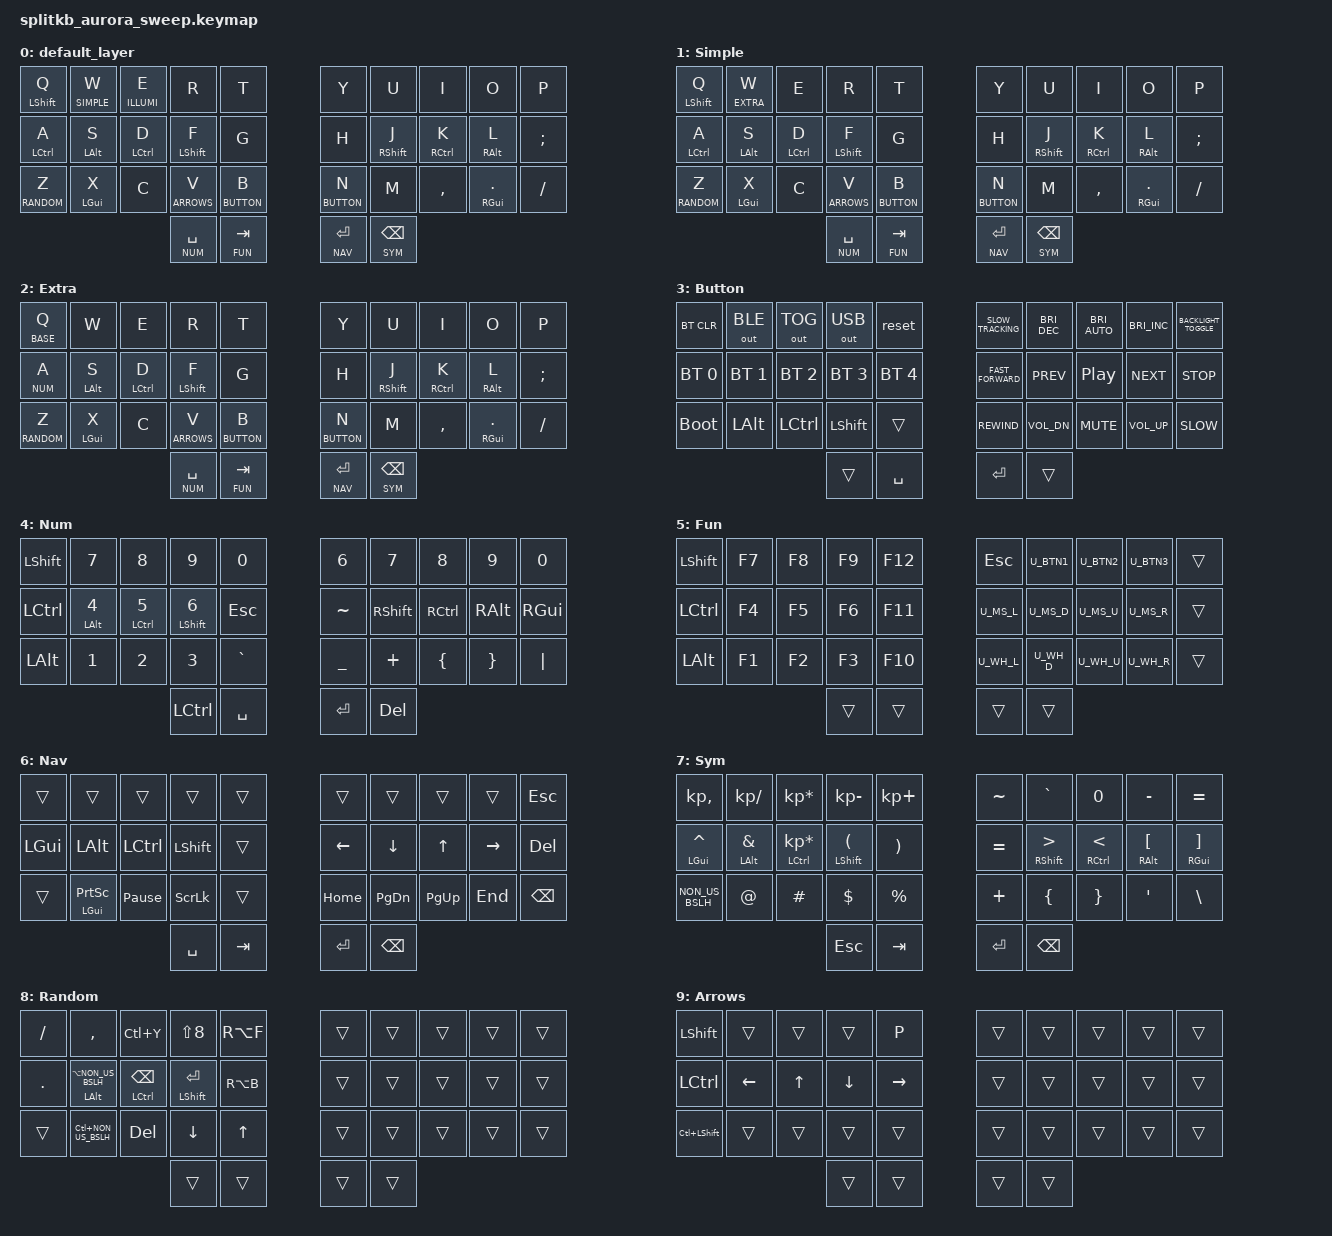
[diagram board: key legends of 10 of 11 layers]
/*
 * Copyright (c) 2020 The ZMK Contributors
 *
 * SPDX-License-Identifier: MIT
 */

#include <behaviors.dtsi>
#include <dt-bindings/zmk/keys.h>
#include <dt-bindings/zmk/bt.h>
#include <dt-bindings/zmk/outputs.h>
#include <dt-bindings/zmk/mouse.h>
#include <dt-bindings/zmk/rgb.h>



#include "mousedefs.h"
// #include <dt-bindings/zmk/backlight.h>

#define BASE   0
#define SIMPLE 1
#define EXTRA  2
#define BUTTON 3
#define NUM    4
#define FUN    5
#define NAV    6
#define SYM    7
#define RANDOM 8
#define ARROWS 9
#define ILLUMI 10

&led_strip {
    chain-length = <23>;
};

/ {
    behaviors {
        hm: homerow_mods {
            compatible = "zmk,behavior-hold-tap";
            label = "homerow mods";
            #binding-cells = <2>;
            tapping_term_ms = <200>;
            flavor = "balanced";
            quick-tap-ms = <0>;
            bindings = <&kp>, <&kp>;
        };
        him: homerow_insta_mods {
            compatible = "zmk,behavior-hold-tap";
            label = "hm_insta_mods";
            #binding-cells = <2>;
			tapping-term-ms = <200>;
            flavor = "balanced";
            bindings = <&kp>, <&kp>;
            // hold-while-undecided;
        };
        hfm: homerow_fastmode {
            compatible = "zmk,behavior-hold-tap";
            label = "HOMEROW_FAST";
            #binding-cells = <2>;
            tapping_term_ms = <300>;
            flavor = "tap-preferred";
            bindings = <&kp>, <&kp>;
            // hold-while-undecided;
        };
        hcm: homerow_crazymode {
            compatible = "zmk,behavior-hold-tap";
            label = "HOMEROW_CRAZY";
            #binding-cells = <2>;
            tapping_term_ms = <0>;
            flavor = "balanced";
            bindings = <&kp>, <&kp>;
            retro-tap;
        };
        ltg: layer_toggler {
            compatible = "zmk,behavior-hold-tap";
            label = "LAYER_TOGGLER";
            #binding-cells = <2>;
            tapping_term_ms = <1200>;
            flavor = "tap-preferred";
            bindings = <&to>, <&kp>;
        };
        ltp: layer_tapper {
            compatible = "zmk,behavior-hold-tap";
            label = "LAYER_TAPPER";
            #binding-cells = <2>;
            tapping_term_ms = <200>;
            flavor = "balanced";
            bindings = <&mo>, <&kp>;
        };
    };
    
    keymap {
        compatible = "zmk,keymap";
        default_layer {
            bindings = <
   &him LSHFT Q    &ltg SIMPLE W  &ltp ILLUMI E  &kp R            &kp T           &kp Y            &kp U          &kp I        &kp O         &kp P
   &hm LCTRL A     &hm LALT S     &hm LCTRL D    &him LSHFT F     &kp G           &kp H            &hm RSHFT J    &hm RCTRL K  &hm RALT L    &kp SEMI
   &ltp RANDOM Z   &hm LGUI X     &kp C          &ltp ARROWS V    &ltp BUTTON B   &ltp BUTTON N    &kp M          &kp COMMA    &hm RGUI DOT  &kp FSLH
                                                 &ltp NUM SPACE   &ltp FUN TAB    &ltp NAV ENTER   &ltp SYM BSPC
            >;
        };
        simple_layer {
            label = "Simple";
// -----------------------------------------------------------------------------------------
// same as base, but smaller times
            bindings = <
   &him LSHFT Q    &ltg EXTRA W    &kp E         &kp R           &kp T           &kp Y           &kp U          &kp I         &kp O          &kp P
   &hm LCTRL A    &hm LALT S      &him LCTRL D   &him LSHFT F    &kp G           &kp H           &hfm RSHFT J   &hfm RCTRL K  &hfm RALT L    &kp SEMI
   &ltp RANDOM Z  &hfm LGUI X     &kp C         &ltp ARROWS V   &ltp BUTTON B   &ltp BUTTON N   &kp M          &kp COMMA     &hfm RGUI DOT  &kp FSLH
                                                &ltp NUM SPACE  &ltp FUN TAB    &ltp NAV ENTER  &ltp SYM BSPC
            >;
        };
        extra_layer {
            label = "Extra";
// -----------------------------------------------------------------------------------------
// Interrup activated modkeys
            bindings = <
   &ltg BASE Q    &kp W        &kp E         &kp R          &kp T           &kp Y          &kp U          &kp I         &kp O          &kp P 
   &ltp NUM A     &hcm LALT S  &hcm LCTRL D  &hfm LSHFT F   &kp G           &kp H          &hcm RSHIFT J  &hcm RCTRL K  &hcm RALT L    &kp SEMI 
   &ltp RANDOM Z  &hcm LGUI X  &kp C         &ltp ARROWS V  &ltp BUTTON B   &ltp BUTTON N  &kp M          &kp COMMA     &hcm RGUI DOT  &kp FSLH
                                             &ltp NUM SPC   &ltp FUN TAB    &ltp NAV RET   &ltp SYM BSPC
            >;
        };
        button_layer {
            label = "Button";
// -----------------------------------------------------------------------------------------
// |       | OBT | OTOG | OUSB | BOOT |   |     |      |       |      |     |
// |  BT1  | BT2 | BT3  | BT4  | BT5  |   |     | PREV | PLAYP | NEXT | STP |
// | BTCLR | BLE | UBT  |      | RST  |   |     | VDN  | MUTE  | VUP  |     |
//                      |      | SPC  |   | ENT | ALT  |
            bindings = <
   &bt BT_CLR    &out OUT_BLE  &out OUT_TOG  &out OUT_USB  &reset         &kp C_SLOW_TRACKING  &kp C_BRI_DEC  &kp C_BRI_AUTO  &kp C_BRI_INC  &kp C_BACKLIGHT_TOGGLE     
   &bt BT_SEL 0  &bt BT_SEL 1  &bt BT_SEL 2  &bt BT_SEL 3  &bt BT_SEL 4   &kp C_FAST_FORWARD   &kp C_PREV     &kp C_PP        &kp C_NEXT     &kp C_STOP 
   &bootloader   &kp LALT      &kp LCTRL     &kp LSHIFT    &trans         &kp C_REWIND         &kp C_VOL_DN   &kp C_MUTE      &kp C_VOL_UP   &kp C_SLOW     
                                             &trans        &kp SPACE      &kp RET              &trans
            >;
        };

        num_layer {
            label = "Num";
// -----------------------------------------------------------------------------------------
// |  SHFT  |  7  |  8  |  9  |  0  |   |  6  |  7  |  8  |  9  |  0  |
// |  CTRL  |  4  |  5  |  6  | ESC |   |  -  |  =  |  [  |  ]  |  \  |
// |  ALT   |  1  |  2  |  3  |  0  |   |  _  |  +  |  {  |  }  | "|" |
//                      |     | SPC |   | ENT | DEL |
            bindings = <
   &kp LSHFT  &kp N7       &kp N8        &kp N9         &kp N0      &kp N6     &kp N7    &kp N8    &kp N9    &kp N0
   &kp LCTRL  &hm LALT N4  &hm LCTRL N5  &hm LSHIFT N6  &kp ESC     &kp TILDE  &kp RSHFT  &kp RCTRL  &kp RALT  &kp RGUI
   &kp LALT   &kp N1       &kp N2        &kp N3         &kp GRAVE   &kp UNDER  &kp PLUS  &kp LBRC  &kp RBRC  &kp PIPE
                    	                 &kp LCTRL      &kp SPACE   &kp RET    &kp DEL
            >;
        };

        fun_layer {
            label = "Fun";
// -----------------------------------------------------------------------------------------
// |  SHFT  |  F9  |  F6   |  F3  |  F12  |   |    |         |               |        |  Bootloader  |   |
// |  CTRL  |  F8  |  F5   |  F2  |  F11  |   |    |  GUI    |      ALT      |  CTRL  |     SHFT     |   |
// |  ALT   |  F7  |  F4   |  F1  |  F10  |   |    |  PSCRN  |  PAUSE_BREAK  |  SLCK  |              |   |
//                         |      |       |   |    |         |
            bindings = <
   &kp LSHFT  &kp F7  &kp F8  &kp F9  &kp F12     &kp ESC  U_BTN1  U_BTN2  U_BTN3  &trans  
   &kp LCTRL  &kp F4  &kp F5  &kp F6  &kp F11     U_MS_L   U_MS_D  U_MS_U  U_MS_R  &trans
   &kp LALT   &kp F1  &kp F2  &kp F3  &kp F10     U_WH_L   U_WH_D  U_WH_U  U_WH_R  &trans
                                 &trans  &trans   &trans   &trans
            >;
        };
        nav_layer {
            label = "Nav";
// -----------------------------------------------------------------------------------------
// |  TAB |     |     |      |      |     |   | SDN | SDN | SCUP | SCUP |     |   |
// | CTRL | GUI | ALT | CTRL | SHFT |     |   | LFT | DWN |  UP  | RGHT |     |   |
// | SHFT |     |     |      |      |     |   | INS | HOM | PGUP | PGDN | END |   |
//                    | ESC  | SPCE | TAB |   | RET | BSP | DEL |
                                           bindings = <
// &bootloader &trans &trans U_NA     U_NA    U_RDO       U_PST    U_CPY   U_CUT  U_UND
   &trans    &trans          &trans           &trans     &trans     &trans       &trans     &trans     &trans     &kp ESC
   &kp LGUI  &kp LALT        &kp LCTRL        &kp LSHFT  &trans     &kp LEFT     &kp DOWN   &kp UP     &kp RIGHT  &kp DEL
   &trans    &hm LGUI PSCRN  &kp PAUSE_BREAK  &kp SLCK   &trans     &kp HOME     &kp PG_DN  &kp PG_UP  &kp END    &kp BSPC
                                              &kp SPACE  &kp TAB    &kp RET      &kp BSPC
            >;
        };
        sym_layer {
            label = "Sym";
// -----------------------------------------------------------------------------------------
// |  ,  |  /  |  *  |  -  |  +  |   |  ~  |  `  |  0  |  Ü  |  Ó  |
// |  ^  |  &  |  *  |  (  |  )  |   |  =  |  <  |  >  | [Ő  | ]Ú  |
// |  !  |  @  |  #  |  $  |  %  |   |  +  |  {  |  }  |  Ő  |  Ű  |
//                    | ESC | SPC | TAB |   | RET | BSP | DEL |
            bindings = <
// &kp PIPE ==? altgr + W;  kp KP_SUBTRACT ==? &kp MINUS; &kp UNDER ==? SHIFT + MINUS; EXCL == Altgr + 4 == "!"       
   &kp KP_COMMA     &kp KP_SLASH   &kp KP_ASTERISK        &kp KP_SUBTRACT  &kp KP_PLUS   &kp TILDE  &kp GRAVE      &kp N0        &kp MINUS      &kp EQUAL
   &hm LGUI CARET   &hm LALT AMPS  &hm LCTRL KP_MULTIPLY  &hm LSHIFT LPAR  &kp RPAR      &kp EQUAL  &hm RSHIFT GT  &hm RCTRL LT  &hm RALT LBKT  &hm RGUI RBKT
   &kp NON_US_BSLH  &kp AT         &kp HASH               &kp DLLR         &kp PRCNT     &kp PLUS   &kp LBRC       &kp RBRC      &kp QUOT       &kp BSLH
                    	                                  &kp ESC          &kp TAB       &kp RET    &kp BSPC
            >;
        };
        random_layer {
            label = "Random";
// -----------------------------------------------------------------------------------------
// |  -  |  ,  | UNDO |  (  |     |   |     |     |     |     |     |
// |  .  |     | BSPC | RET |     |   |     |     |     |     |     |
// |     |     | DEL  |     |     |   |     |     |     |     |     |
//                    |     |     |   |     |     |
            bindings = <    
   &kp FSLH  &kp COMMA                 &kp LC(Y)       &kp LS(N8)        &kp RA(F)   &trans  &trans  &trans  &trans  &trans
   &kp DOT   &hm LALT LA(NON_US_BSLH)  &hm LCTRL BSPC  &hm LSHIFT ENTER  &kp RA(B)   &trans  &trans  &trans  &trans  &trans 
   &trans    &kp LC(NON_US_BSLH)       &kp DEL         &kp DOWN          &kp UP      &trans  &trans  &trans  &trans  &trans
                    	                               &trans            &trans      &trans  &trans
            >;
        };
        arrows {
            label = "Arrows";
// -----------------------------------------------------------------------------------------
// |     |      |     |     |  P   |   |     |     |     |     |     |
// |     |  LFT | UP  | DWN | RGHT |   |     |     |     |     |     |
// |     |      |     |     |      |   |     |     |     |     |     |
//                    |     |      |   |     |     |
// LC(SHFT(P)) available. Ctrl moves.
            bindings = <    
   &kp LSHFT      &trans    &trans  &trans    &kp P       &trans  &trans  &trans  &trans  &trans
   &kp LCTRL      &kp LEFT  &kp UP  &kp DOWN  &kp RIGHT   &trans  &trans  &trans  &trans  &trans 
   &kp LC(LSHFT)  &trans    &trans  &trans    &trans      &trans  &trans  &trans  &trans  &trans
                    	            &trans    &trans      &trans  &trans
            >;
        };
        illumi_layer {
            label = "Illuminati";
// -----------------------------------------------------------------------------------------
// |     |     |     |    |    |   |     |     |     |     |     |
// |     |     |     |    |    |   |     |     |     |     |     |
// |     |     |     |    |    |   |     |     |     |     |     |
//                   |    |    |   |     |     |
            bindings = <    
   &trans  &trans     &trans  &trans  &trans   &rgb_ug RGB_BRI  &rgb_ug RGB_BRD   &rgb_ug RGB_COLOR_HSB(1 ,100, 55)  &rgb_ug RGB_COLOR_HSB(33, 100, 55)  &rgb_ug RGB_COLOR_HSB(217, 98, 86)
   &trans  &kp LA(Z)  &trans  &trans  &trans   &rgb_ug RGB_SAI  &rgb_ug RGB_SAD   &rgb_ug RGB_COLOR_HSB(15,100, 55)  &rgb_ug RGB_COLOR_HSB(192,100,100)  &rgb_ug RGB_EFF
   &trans  &trans     &trans  &trans  &trans   &rgb_ug RGB_HUI  &rgb_ug RGB_HUD   &rgb_ug RGB_COLOR_HSB(25,  0,100)  &rgb_ug RGB_COLOR_HSB(128,100,100)  &rgb_ug RGB_EFR
                    	      &trans  &trans   &trans           &trans
            >;
        };
    };
};
